# PIC32MM0032GPL036 device description
Architecture: MIPS; Family: PIC32MM1324; Series: PIC32MM
Registers are 32-bit, read-write, no defined reset value unless marked. A register's access mark holds for its fields unless they carry their own. Offsets are from the block's base; [hi:lo] are bit positions; lines under a group give offsets from that group; {n}, {i} and the like mark numbered series.

## INT
Instances: INT 0x1f802300 in periph0
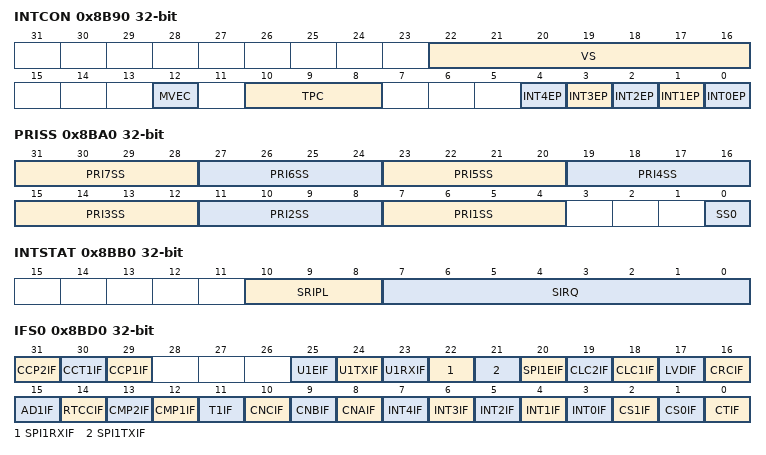
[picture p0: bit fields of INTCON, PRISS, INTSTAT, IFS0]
0x8B90 INTCON — Interrupt Control Register
  [22:16] VS
  [12] MVEC — Multi Vector Configuration bit
    1=Interrupt controller configured for multi vectored mode; 0=Interrupt controller configured for single vectored mode
  [10:8] TPC — Interrupt Proximity Timer Control bits
    {v}=Interrupts of group priority {v} or lower start the Interrupt Proximity timer (v=2..7); 1=Interrupts of group priority 1 start the Interrupt Proximity timer; 0=Disables Interrupt Proximity timer
  [n] INT{n}EP (n=0..4) — External Interrupt {n} Edge
    1=Rising edge; 0=Falling edge
0x8BA0 PRISS
  [4n+3:4n] PRI{n}SS (n=1..7)
  [0] SS0 — Single Vector Shadow Register Set bit
    1=Single vector is presented with a shadow register set; 0=Single vector is not presented with a shadow register set
0x8BB0 INTSTAT ro
  [10:8] SRIPL, [7:0] SIRQ
0x8BC0 IPTMR
0x8BD0 IFS0
  [31] CCP2IF, [30] CCT1IF, [29] CCP1IF, [25] U1EIF, [24] U1TXIF, [23] U1RXIF, [22] SPI1RXIF, [21] SPI1TXIF, [20] SPI1EIF, [19] CLC2IF, [18] CLC1IF, [17] LVDIF, [16] CRCIF, [15] AD1IF, [14] RTCCIF, [13] CMP2IF, [12] CMP1IF, [11] T1IF, [10] CNCIF, [9] CNBIF, [8] CNAIF, [n+3] INT{n}IF (n=0..4), [2] CS1IF, [1] CS0IF, [0] CTIF
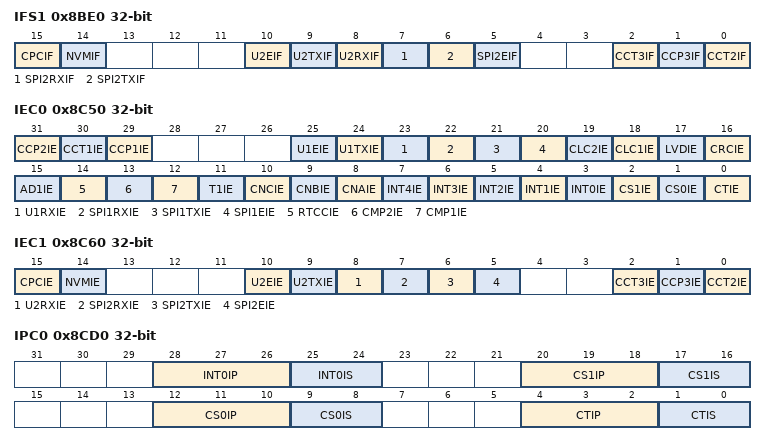
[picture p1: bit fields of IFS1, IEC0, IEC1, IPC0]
0x8BE0 IFS1
  [15] CPCIF, [14] NVMIF, [10] U2EIF, [9] U2TXIF, [8] U2RXIF, [7] SPI2RXIF, [6] SPI2TXIF, [5] SPI2EIF, [2] CCT3IF, [1] CCP3IF, [0] CCT2IF
0x8C50 IEC0
  [31] CCP2IE, [30] CCT1IE, [29] CCP1IE, [25] U1EIE, [24] U1TXIE, [23] U1RXIE, [22] SPI1RXIE, [21] SPI1TXIE, [20] SPI1EIE, [19] CLC2IE, [18] CLC1IE, [17] LVDIE, [16] CRCIE, [15] AD1IE, [14] RTCCIE, [13] CMP2IE, [12] CMP1IE, [11] T1IE, [10] CNCIE, [9] CNBIE, [8] CNAIE, [n+3] INT{n}IE (n=0..4), [2] CS1IE, [1] CS0IE, [0] CTIE
0x8C60 IEC1
  [15] CPCIE, [14] NVMIE, [10] U2EIE, [9] U2TXIE, [8] U2RXIE, [7] SPI2RXIE, [6] SPI2TXIE, [5] SPI2EIE, [2] CCT3IE, [1] CCP3IE, [0] CCT2IE
0x8CD0 IPC0
  [28:26] INT0IP, [25:24] INT0IS, [20:18] CS1IP, [17:16] CS1IS, [12:10] CS0IP, [9:8] CS0IS, [4:2] CTIP, [1:0] CTIS
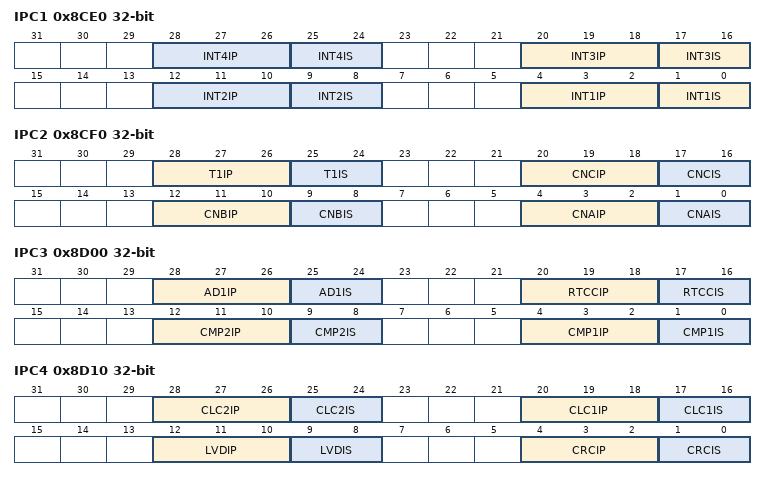
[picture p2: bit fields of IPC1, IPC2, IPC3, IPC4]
0x8CE0 IPC1
  [8n-4:8n-6] INT{n}IP (n=1..4), [8n-7:8n-8] INT{n}IS (n=1..4)
0x8CF0 IPC2
  [28:26] T1IP, [25:24] T1IS, [20:18] CNCIP, [17:16] CNCIS, [12:10] CNBIP, [9:8] CNBIS, [4:2] CNAIP, [1:0] CNAIS
0x8D00 IPC3
  [28:26] AD1IP, [25:24] AD1IS, [20:18] RTCCIP, [17:16] RTCCIS, [12:10] CMP2IP, [9:8] CMP2IS, [4:2] CMP1IP, [1:0] CMP1IS
0x8D10 IPC4
  [28:26] CLC2IP, [25:24] CLC2IS, [20:18] CLC1IP, [17:16] CLC1IS, [12:10] LVDIP, [9:8] LVDIS, [4:2] CRCIP, [1:0] CRCIS
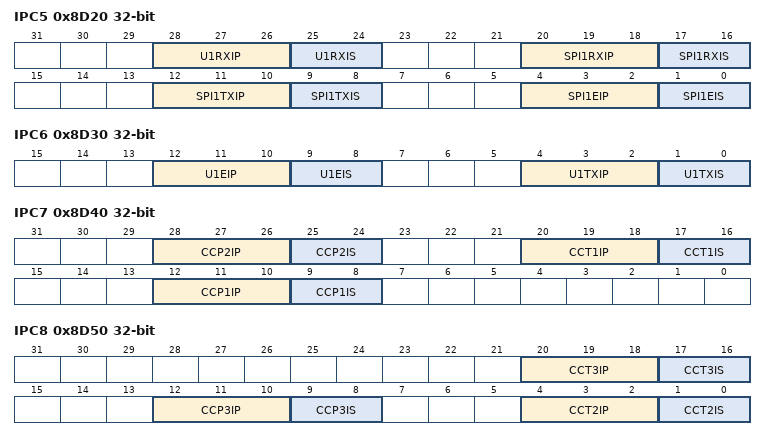
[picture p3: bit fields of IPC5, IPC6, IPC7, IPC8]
0x8D20 IPC5
  [28:26] U1RXIP, [25:24] U1RXIS, [20:18] SPI1RXIP, [17:16] SPI1RXIS, [12:10] SPI1TXIP, [9:8] SPI1TXIS, [4:2] SPI1EIP, [1:0] SPI1EIS
0x8D30 IPC6
  [12:10] U1EIP, [9:8] U1EIS, [4:2] U1TXIP, [1:0] U1TXIS
0x8D40 IPC7
  [28:26] CCP2IP, [25:24] CCP2IS, [20:18] CCT1IP, [17:16] CCT1IS, [12:10] CCP1IP, [9:8] CCP1IS
0x8D50 IPC8
  [20:18] CCT3IP, [17:16] CCT3IS, [12:10] CCP3IP, [9:8] CCP3IS, [4:2] CCT2IP, [1:0] CCT2IS
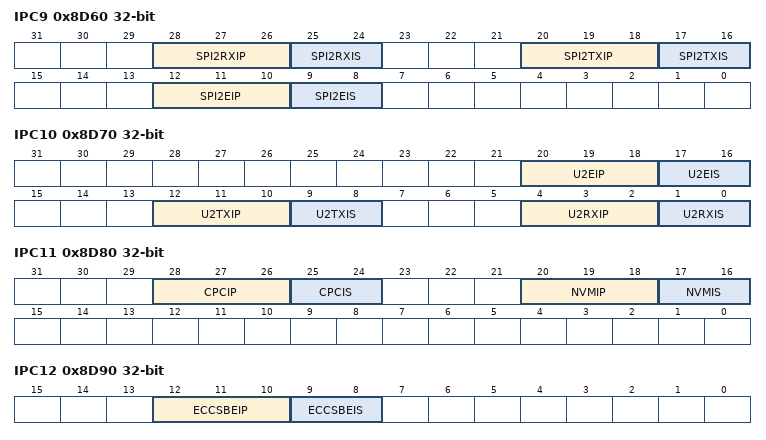
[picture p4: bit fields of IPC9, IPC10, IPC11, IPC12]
0x8D60 IPC9
  [28:26] SPI2RXIP, [25:24] SPI2RXIS, [20:18] SPI2TXIP, [17:16] SPI2TXIS, [12:10] SPI2EIP, [9:8] SPI2EIS
0x8D70 IPC10
  [20:18] U2EIP, [17:16] U2EIS, [12:10] U2TXIP, [9:8] U2TXIS, [4:2] U2RXIP, [1:0] U2RXIS
0x8D80 IPC11
  [28:26] CPCIP, [25:24] CPCIS, [20:18] NVMIP, [17:16] NVMIS
0x8D90 IPC12
  [12:10] ECCSBEIP, [9:8] ECCSBEIS

## NVM
Instances: NVM 0x1f802380 in periph0
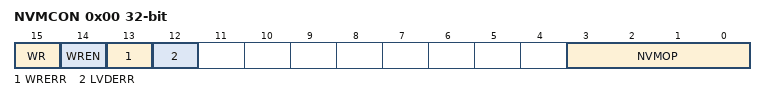
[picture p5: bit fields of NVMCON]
0x00 NVMCON
  [15] WR, [14] WREN, [13] WRERR, [12] LVDERR, [3:0] NVMOP

## RCON
Instances: RCON 0x1f802000 in periph0
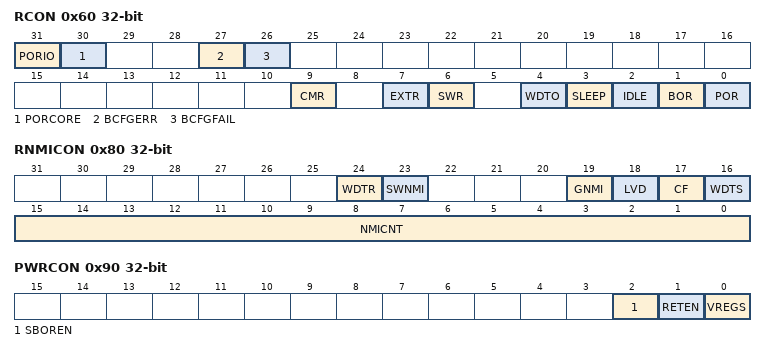
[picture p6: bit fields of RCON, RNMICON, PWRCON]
0x60 RCON — Reset Control Register
  [31] PORIO
  [30] PORCORE
  [27] BCFGERR
  [26] BCFGFAIL
  [9] CMR — Configuration Mismatch Reset Flag bit
    1=A Configuration Mismatch Reset has occurred; 0=A Configuration Mismatch Reset has not occurred
  [7] EXTR — External Reset Pin Flag bit
    1=Master Clear (pin) Reset has occurred; 0=Master Clear (pin) Reset has not occurred
  [6] SWR — Software Reset Flag bit
    1=Software Reset was executed; 0=Software Reset was not executed
  [4] WDTO — Watchdog Timer Time-out Flag bit
    1=WDT Time-out has occurred; 0=WDT Time-out has not occurred
  [3] SLEEP — Wake From Sleep Flag bit
    1=Device was in Sleep mode; 0=Device was not in Sleep mode
  [2] IDLE — Wake From Idle Flag bit
    1=Device was in Idle mode; 0=Device was not in Idle mode
  [1] BOR — Brown-out Reset Flag bit
    1=Brown-out Reset has occurred; 0=Brown-out Reset has not occurred
  [0] POR — Power-on Reset Flag bit
    1=Power-on Reset has occurred; 0=Power-on Reset has not occurred
0x70 RSWRST wo
  [0] SWRST
0x80 RNMICON — Non-Maskable Interrupt (NMI) Control Register
  [24] WDTR — Run Time Watchdog Timer Time-Out Flag bit
    1=WDT time-out has occurred and caused a NMI; 0=WDT time-out has not occurred
  [23] SWNMI — Software NMI Trigger
    1=An NMI will be generated; 0=An NMI will not be generated
  [19] GNMI — General NMI bit
    1=A general NMI event has been detected or a user-initiated NMI event has occurred; 0=A general NMI event has not been detected
  [18] LVD
  [17] CF — Clock Fail Detect bit
    1=FSCM has detected clock failure and caused an NMI; 0=FSCM has not detected clock failure
  [16] WDTS — Watchdog Timer Time-out in Sleep Mode Flag bit
    1=WDT time-out has occurred during Sleep mode and caused a wake-up from sleep; 0=WDT time-out has not occurred during Sleep mode
  [15:0] NMICNT — NMI Reset Counter Value bits
    0xffff=65535 SYSCLK cycles before a device Reset occurs; 2=2 SYSCLK cycle before a device Reset occurs; 1=1 SYSCLK cycle before a device Reset occurs; 0=No delay between NMI assertion and device Reset event
0x90 PWRCON
  [2] SBOREN
  [1] RETEN
  [0] VREGS — Voltage Regulator Stand-by Enable bit
    1=Voltage regulator will remain active during Sleep; 0=Voltage regulator will go to Stand-by mode during Sleep
